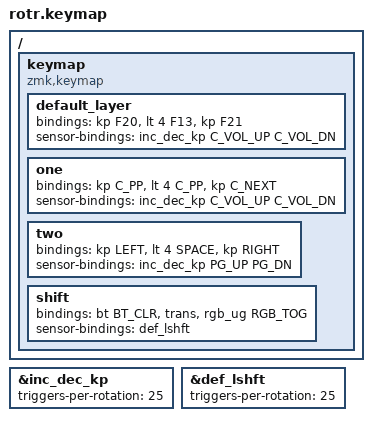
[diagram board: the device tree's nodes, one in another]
#include <behaviors.dtsi>
#include <dt-bindings/zmk/keys.h>
#include <dt-bindings/zmk/rgb.h>
#include <dt-bindings/zmk/bt.h>

&inc_dec_kp {
	triggers-per-rotation = <25>;
};
&def_lshft {
	triggers-per-rotation = <25>;
};

/ {
	keymap {
		compatible = "zmk,keymap";

		default_layer {
			//PREV | PLAY/PAUSE | NEXT
			bindings = <&kp F20 &lt 4 F13 &kp F21>;
			sensor-bindings = <&inc_dec_kp C_VOL_UP C_VOL_DN>;
		};
		one {
			//PREV | PLAY/PAUSE | NEXT
			bindings = <&kp C_PP &lt 4 C_PP &kp C_NEXT>;
			sensor-bindings = <&inc_dec_kp C_VOL_UP C_VOL_DN>;
		};
		two {
			//PREV | PLAY/PAUSE | NEXT
			bindings = <&kp LEFT &lt 4 SPACE &kp RIGHT>;
			sensor-bindings = <&inc_dec_kp PG_UP PG_DN>;
		};
		shift {
			//PREV | PLAY/PAUSE | NEXT
			bindings = <&bt BT_CLR &trans &rgb_ug RGB_TOG>;
			sensor-bindings = <&def_lshft>;
		};
	};
};
